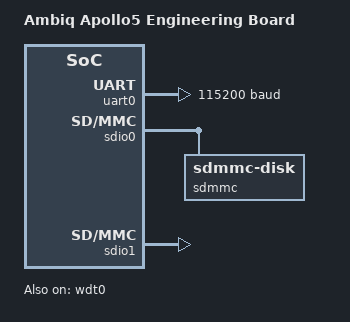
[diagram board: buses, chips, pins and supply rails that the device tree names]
/dts-v1/;
#include <ambiq/ambiq_apollo5.dtsi>

#include "apollo5_eb-pinctrl.dtsi"

/ {
	model = "Ambiq Apollo5 Engineering Board";
	compatible = "ambiq,apollo5_eb";

	chosen {
		zephyr,itcm = &itcm;
		zephyr,dtcm = &dtcm;
		zephyr,sram = &sram0;
		zephyr,flash = &flash0;
		zephyr,console = &uart0;
		zephyr,shell-uart = &uart0;
		zephyr,uart-pipe = &uart0;
	};

	aliases {
		watchdog0 = &wdt0;
		sdhc0 = &sdio0;
		sdhc1 = &sdio1;
	};
};

&itm {
	pinctrl-0 = <&swo_default>;
	pinctrl-names = "default";
};

&uart0 {
	current-speed = <115200>;
	pinctrl-0 = <&uart0_default>;
	pinctrl-names = "default";
	status = "okay";
};

&wdt0 {
	status = "okay";
};

&sdio0 {
	pinctrl-0 = <&sdio0_default>;
	pinctrl-names = "default";
	txdelay = <0>;
	rxdelay = <0>;
	status = "okay";
	sdmmc {
		compatible = "zephyr,sdmmc-disk";
		status = "okay";
	};
};

&sdio1 {
	pinctrl-0 = <&sdio1_default>;
	pinctrl-names = "default";
	txdelay = <9>;
	rxdelay = <11>;
	status = "okay";
};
